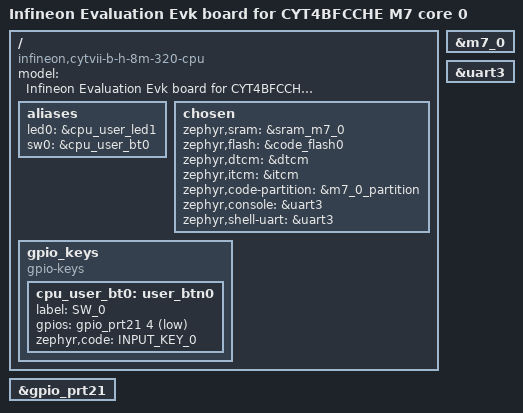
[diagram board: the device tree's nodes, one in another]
/*
 * Copyright (c) 2026 Infineon Technologies AG,
 * or an affiliate of Infineon Technologies AG.
 * Copyright (c) 2026 Linumiz
 *
 * SPDX-License-Identifier: Apache-2.0
 */

/dts-v1/;
#include <arm/infineon/cat1c/traveo/cyt4bf/cyt4bf_m7.dtsi>
#include "cytvii_b_h_8m_320_cpu_common.dtsi"
#include "cytvii_b_h_8m_320_cpu_cyt4bfcche_pinctrl.dtsi"

/ {
	model = "Infineon Evaluation Evk board for CYT4BFCCHE M7 core 0";
	compatible = "infineon,cytvii-b-h-8m-320-cpu", "infineon,cyt4bf";

	aliases {
                led0 = &cpu_user_led1;
                sw0 = &cpu_user_bt0;
        };

	chosen {
		zephyr,sram = &sram_m7_0;
		zephyr,flash = &code_flash0;
		zephyr,dtcm = &dtcm;
		zephyr,itcm = &itcm;
		zephyr,code-partition = &m7_0_partition;
		zephyr,console = &uart3;
		zephyr,shell-uart = &uart3;
	};

	gpio_keys {
                compatible = "gpio-keys";

                cpu_user_bt0: user_btn0 {
                        label = "SW_0";
                        gpios = <&gpio_prt21 4 (GPIO_PULL_UP | GPIO_ACTIVE_LOW)>;
                        zephyr,code = <INPUT_KEY_0>;
                };
        };
};

&m7_0 {
	status = "okay";
};

&uart3 {
	status = "okay";
};

&gpio_prt21 {
	status = "okay";
};
